# SC000 register map
Vendor: Arm Ltd.; Series: ARMv6-M; File version: 1.0.0
CPU: SC000 r0p0, little endian, MPU, no FPU, 2 interrupt priority bits
Registers are 32-bit, read-write, reset 0x0 unless marked. A register's access mark holds for its fields unless they carry their own. Offsets are from the block's base; [hi:lo] are bit positions.

## SCB — System Control Block: CPUID, exception control and state (ICSR, AIRCR, SHCSR), system configuration (SCR, CCR), system handler priorities, the fault status and address registers (CFSR, HFSR, DFSR, MMFAR, BFAR), CPU feature IDs, coprocessor access control, and on cores with caches the cache ID and maintenance registers.
Base 0xE000ED00
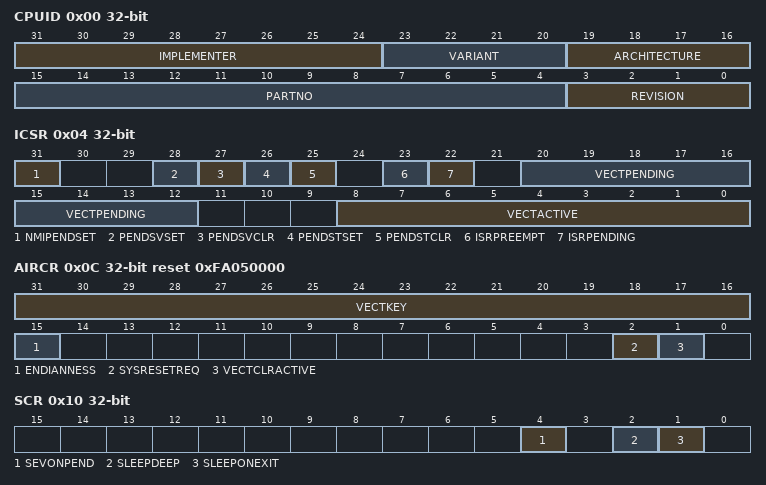
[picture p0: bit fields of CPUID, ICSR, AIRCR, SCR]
0x00 CPUID ro — CPUID Base Register: implementer, part number, architecture and revision of the processor (read-only).
  [31:24] IMPLEMENTER — Implementer code: 0x41 = Arm.
  [23:20] VARIANT — Major revision rN of the rNpM product revision.
  [19:16] ARCHITECTURE — Architecture: 0xC = ARMv6-M, 0xF = ARMv7-M or ARMv8-M (use ID_PFR/ID_ISAR for the details).
  [15:4] PARTNO — Part number: 0xC20 Cortex-M0, 0xC60 Cortex-M0+, 0xC21 Cortex-M1, 0xC23 Cortex-M3, 0xC24 Cortex-M4, 0xC27 Cortex-M7, 0xD20 Cortex-M23, 0xD21 Cortex-M33, 0xD31 Cortex-M35P, 0xD22 Cortex-M55, 0xD23 Cortex-M85, 0xD24 Cortex-M52.
  [3:0] REVISION — Minor revision pM of the rNpM product revision.
0x04 ICSR — Interrupt Control and State Register: active and pending exception numbers, and set/clear-pending controls for NMI, PendSV and SysTick.
  [31] NMIPENDSET — Write 1 to set NMI pending; NMI is taken at once unless a higher active priority (another NMI, HardFault at -1 is lower) or Debug state prevents it. Reads 1 while pending.
  [28] PENDSVSET — Write 1 to set PendSV pending (the usual RTOS context-switch trigger); reads 1 while it is pending.
  [27] PENDSVCLR wo — Write 1 to clear a pending PendSV. Reads as 0.
  [26] PENDSTSET — Write 1 to set the SysTick exception pending; reads 1 while it is pending.
  [25] PENDSTCLR wo — Write 1 to clear a pending SysTick exception. Reads as 0.
  [23] ISRPREEMPT ro — 1 = a pending exception will be serviced when the processor leaves Debug state (debug use only).
  [22] ISRPENDING ro — 1 = an external interrupt (IRQ, not NMI or a fault) is pending.
  [20:12] VECTPENDING ro — Exception number of the highest-priority pending enabled exception, 0 if none. Not affected by PRIMASK/FAULTMASK/BASEPRI.
  [8:0] VECTACTIVE ro — Exception number of the currently executing handler; 0 in Thread mode. 2 NMI, 3 HardFault, 4 MemManage, 5 BusFault, 6 UsageFault, 7 SecureFault, 11 SVCall, 12 DebugMonitor, 14 PendSV, 15 SysTick, 16+n IRQn.
0x08 VTOR — Vector Table Offset Register: base address of the exception vector table. Must be aligned to the table size rounded up to a power of two (at least 128 bytes). Reset value is implementation defined (usually 0; set by SystemInit when the table is relocated).
  [31:7] TBLOFF — Vector table base address. The table must be aligned to its size rounded up to a power of two (at least 128 bytes; the low bits read as zero).
0x0C AIRCR reset 0xFA050000 — Application Interrupt and Reset Control Register: priority grouping, endianness, system reset request and (ARMv8-M) security attribution of BusFault/HardFault/NMI. Writes must place 0x05FA in VECTKEY or are ignored.
  [31:16] VECTKEY — Register key: writes must contain 0x05FA here or the whole write is ignored. Reads as 0xFA05 (VECTKEYSTAT).
  [15] ENDIANNESS ro — Data endianness: 0 = little-endian, 1 = big-endian (BE8). Read-only, sampled at reset.
    0=Little-endian data; 1=Big (Big-endian (BE8) data)
  [2] SYSRESETREQ — Write 1 (with VECTKEY = 0x05FA) to request a system reset (asserts SYSRESETREQ to the reset controller). Self-clearing; NVIC_SystemReset() uses this.
  [1] VECTCLRACTIVE — Debug use only: write 1 (with VECTKEY) to clear all active-exception state. Only while halted; otherwise unpredictable.
0x10 SCR — System Control Register: sleep-on-exit, deep sleep selection and send-event-on-pending.
  [4] SEVONPEND — Send Event on Pending: 1 = an interrupt becoming pending (even a disabled one) wakes the processor from WFE, enabling the WFE-polling idle pattern.
  [2] SLEEPDEEP — 1 = WFI, WFE and sleep-on-exit request deep sleep (SLEEPDEEP output; the implementation-defined low-power mode, often stopping clocks/PLL) instead of sleep.
  [1] SLEEPONEXIT — 1 = the processor sleeps (as after WFI) whenever it returns from an exception handler to Thread mode. Interrupt-driven designs run entirely from handlers this way.
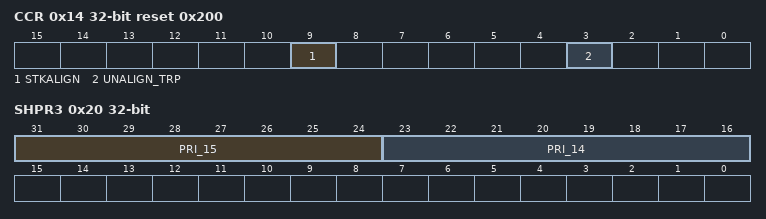
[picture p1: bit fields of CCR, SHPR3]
0x14 CCR reset 0x200 — Configuration and Control Register: trapping of divide-by-zero and unaligned accesses, stack alignment, unprivileged STIR access, Thread-mode return rules, and on cached cores the instruction/data cache and branch predictor enables.
  [9] STKALIGN — 1 = the exception stack frame is 8-byte aligned (the stacked xPSR bit 9 records the adjustment). Always 1 on ARMv8-M and ARMv6-M; on ARMv7-M reset value 1 since r2p0.
  [3] UNALIGN_TRP — 1 = unaligned halfword/word loads and stores raise an UNALIGNED UsageFault. Multi-word accesses (LDM/STM/LDRD/STRD) always fault when unaligned. Always 1 on ARMv6-M.
0x1C SHPR2 — System Handler Priority Register 2: priority of SVCall. Only the top nvicPrioBits of each byte are implemented.
  [31:24] PRI_11 — Priority of system handler 11, SVCall.
0x20 SHPR3 — System Handler Priority Register 3: priorities of PendSV and SysTick. Only the top nvicPrioBits of each byte are implemented.
  [31:24] PRI_15 — Priority of system handler 15, SysTick.
  [23:16] PRI_14 — Priority of system handler 14, PendSV.
0x24 SHCSR — System Handler Control and State Register: enable bits for the configurable fault exceptions and the active/pending state of every system handler. A configurable fault whose enable bit is 0 escalates to HardFault.
  [15] SVCALLPENDED — SVCall pending.
0x290 SFCR — Security Features Control Register
